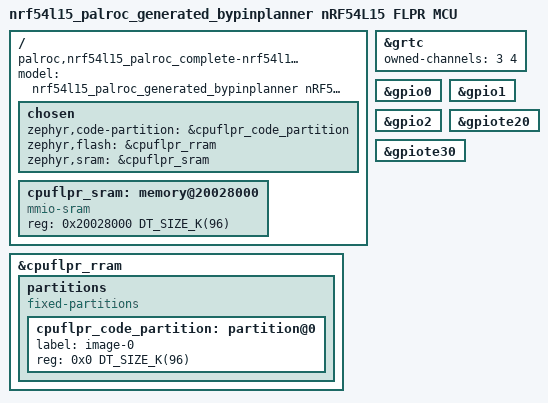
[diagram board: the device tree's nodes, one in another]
/dts-v1/;
#include <nordic/nrf54l15_cpuflpr.dtsi>
#include "nrf54l15_palroc_complete_common.dtsi"

/delete-node/ &cpuflpr_sram;

/ {
	model = "nrf54l15_palroc_generated_bypinplanner nRF54L15 FLPR MCU";
	compatible = "palroc,nrf54l15_palroc_complete-nrf54l15-cpuflpr";

	chosen {
		zephyr,code-partition = &cpuflpr_code_partition;
		zephyr,flash = &cpuflpr_rram;
		zephyr,sram = &cpuflpr_sram;
	};

	cpuflpr_sram: memory@20028000 {
		compatible = "mmio-sram";
		/* Size must be increased due to booting from SRAM */
		reg = <0x20028000 DT_SIZE_K(96)>;
		#address-cells = <1>;
		#size-cells = <1>;
		ranges = <0x0 0x20028000 98304>;
		status = "okay";
	};
};

&cpuflpr_rram {
	partitions {
		compatible = "fixed-partitions";
		#address-cells = <1>;
		#size-cells = <1>;
		ranges;

		cpuflpr_code_partition: partition@0 {
			label = "image-0";
			reg = <0x0 DT_SIZE_K(96)>;
		};
	};
};

&grtc {
	owned-channels = <3 4>;
	status = "okay";
};

&gpio0 {
	status = "okay";
};

&gpio1 {
	status = "okay";
};


&gpio2 {
	status = "okay";
};


&gpiote20 {
	status = "okay";
};

&gpiote30 {
	status = "okay";
};
